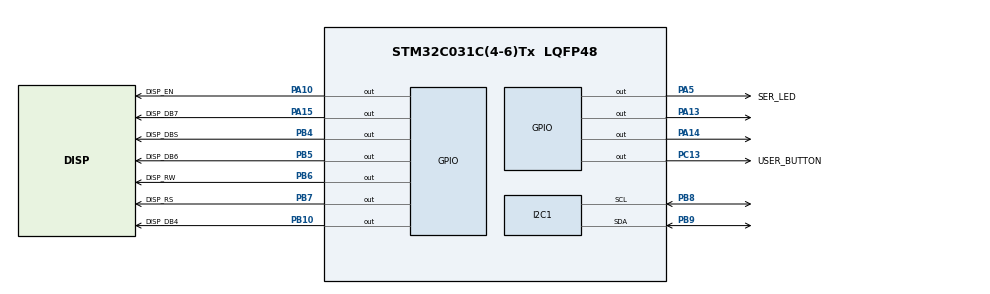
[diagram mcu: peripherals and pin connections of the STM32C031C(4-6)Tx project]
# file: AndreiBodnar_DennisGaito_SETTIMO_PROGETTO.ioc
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I2C1.Timing=0x10805D88
Mcu.Family=STM32C0
Mcu.Name=STM32C031C(4-6)Tx
Mcu.Package=LQFP48
PA10.GPIO_Label=DISP_EN
PA10.Signal=GPIO_Output
PA13.Signal=GPIO_Output
PA14-BOOT0.Signal=GPIO_Output
PA15.GPIO_Label=DISP_DB7
PA15.Signal=GPIO_Output
PA2.GPIO_Label=VCP_USART2_TX
PA2.Signal=USART2_TX
PA3.Signal=USART2_RX
PA5.GPIO_Label=SER_LED
PA5.Signal=GPIO_Output
PB10.GPIO_Label=DISP_DB4
PB10.Signal=GPIO_Output
PB4.GPIO_Label=DISP_DBS
PB4.Signal=GPIO_Output
PB5.GPIO_Label=DISP_DB6
PB5.Signal=GPIO_Output
PB6.GPIO_Label=DISP_RW
PB6.Signal=GPIO_Output
PB7.GPIO_Label=DISP_RS
PB7.Signal=GPIO_Output
PB8.Mode=I2C
PB8.Signal=I2C1_SCL
PB9.Mode=I2C
PB9.Signal=I2C1_SDA
PC13.GPIO_Label=USER_BUTTON
PC13.Signal=GPIO_Output
PC14-OSCX_IN\ (PC14).GPIO_Label=RCC_OSCX_IN
PC14-OSCX_IN\ (PC14).Mode=LSE-External-Oscillator
PC14-OSCX_IN\ (PC14).Signal=RCC_OSCX_IN
PC15-OSCX_OUT\ (PC15).GPIO_Label=RCC_OSCX_OUT
PC15-OSCX_OUT\ (PC15).Mode=LSE-External-Oscillator
PC15-OSCX_OUT\ (PC15).Signal=RCC_OSCX_OUT
PF0-OSC_IN\ (PF0).GPIO_Label=RCC_OSC_IN
PF0-OSC_IN\ (PF0).Mode=HSE-External-Oscillator
PF0-OSC_IN\ (PF0).Signal=RCC_OSC_IN
PF1-OSC_OUT\ (PF1).GPIO_Label=RCC_OSC_OUT
PF1-OSC_OUT\ (PF1).Mode=HSE-External-Oscillator
PF1-OSC_OUT\ (PF1).Signal=RCC_OSC_OUT
ProjectManager.HeapSize=0x200
ProjectManager.StackSize=0x400
ProjectManager.TargetToolchain=STM32CubeIDE
RCC.ADCFreq_Value=48000000
RCC.AHBFreq_Value=48000000
RCC.CortexFreq_Value=48000000
RCC.EXTERNAL_CLOCK_VALUE=12288000
RCC.HCLKFreq_Value=48000000
RCC.HSE_VALUE=48000000
RCC.HSISYSCLKDivider=RCC_HSI_DIV1
RCC.HSI_VALUE=48000000
RCC.SYSCLKFreq_VALUE=48000000
RCC.SYSCLKSource=RCC_SYSCLKSOURCE_HSE
board=NUCLEO-C031C6

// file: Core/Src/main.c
/* USER CODE BEGIN Header */
/**
  ******************************************************************************
  * @file           : main.c
  * @brief          : Main program body
  ******************************************************************************
  * @attention
  *
  * Copyright (c) 2026 STMicroelectronics.
  * All rights reserved.
  *
  * This software is licensed under terms that can be found in the LICENSE file
  * in the root directory of this software component.
  * If no LICENSE file comes with this software, it is provided AS-IS.
  *
  ******************************************************************************
  */
/* USER CODE END Header */
#include "main.h"

/* USER CODE BEGIN PD */
/* USER CODE BEGIN PD */
// Indirizzo shiftato a sinistra (0x18 << 1 = 0x30 oppure 0x19 << 1 = 0x32)
// Proviamo 0x30 (SDO a GND). Se non va, cambia in 0x32 dopo.
#define LIS2DW12_ADDR      0x3
#define LIS2DW12_WHO_REG   0x0F
#define LIS2DW12_WHO_VAL   0x44
/* USER CODE END PD */

I2C_HandleTypeDef hi2c1;

/* USER CODE BEGIN PV */
/* USER CODE BEGIN PV */
uint8_t sensor_id = 0;
HAL_StatusTypeDef ret_tx;
HAL_StatusTypeDef ret_rx;
uint8_t reg_to_read = LIS2DW12_WHO_REG;
/* USER CODE END PV */

void SystemClock_Config(void);
static void MX_GPIO_Init(void);
static void MX_I2C1_Init(void);

int main(void)
{

  /* USER CODE BEGIN 1 */
	HAL_StatusTypeDef ret; // Aggiungi questa variabile per il controllo
  /* USER CODE END 1 */

  /* MCU Configuration--------------------------------------------------------*/

  /* Reset of all peripherals, Initializes the Flash interface and the Systick. */
  HAL_Init();

  /* Configure the system clock */
  SystemClock_Config();

  /* Initialize all configured peripherals */
  MX_GPIO_Init();
  MX_I2C1_Init();
  /* USER CODE BEGIN 2 */
  /* USER CODE BEGIN 2 */

  // 1. Diciamo al sensore quale registro vogliamo leggere (Slide 29)
  ret_tx = HAL_I2C_Master_Transmit(&hi2c1, LIS2DW12_ADDR, &reg_to_read, 1, 100);

  // 2. Se la trasmissione è andata bene, leggiamo il risultato
  if (ret_tx == HAL_OK) {
      ret_rx = HAL_I2C_Master_Receive(&hi2c1, LIS2DW12_ADDR, &sensor_id, 1, 100);
  }

  /* USER CODE END 2 */

  /* Infinite loop */
  while (1)
  {

  }
}

void SystemClock_Config(void)
{
  RCC_OscInitTypeDef RCC_OscInitStruct = {0};
  RCC_ClkInitTypeDef RCC_ClkInitStruct = {0};

  __HAL_FLASH_SET_LATENCY(FLASH_LATENCY_1);

  /** Initializes the RCC Oscillators according to the specified parameters
  * in the RCC_OscInitTypeDef structure.
  */
  RCC_OscInitStruct.OscillatorType = RCC_OSCILLATORTYPE_HSE;
  RCC_OscInitStruct.HSEState = RCC_HSE_ON;
  if (HAL_RCC_OscConfig(&RCC_OscInitStruct) != HAL_OK)
  {
    Error_Handler();
  }

  /** Initializes the CPU, AHB and APB buses clocks
  */
  RCC_ClkInitStruct.ClockType = RCC_CLOCKTYPE_HCLK|RCC_CLOCKTYPE_SYSCLK
                              |RCC_CLOCKTYPE_PCLK1;
  RCC_ClkInitStruct.SYSCLKSource = RCC_SYSCLKSOURCE_HSE;
  RCC_ClkInitStruct.SYSCLKDivider = RCC_SYSCLK_DIV1;
  RCC_ClkInitStruct.AHBCLKDivider = RCC_HCLK_DIV1;
  RCC_ClkInitStruct.APB1CLKDivider = RCC_APB1_DIV1;

  if (HAL_RCC_ClockConfig(&RCC_ClkInitStruct, FLASH_LATENCY_1) != HAL_OK)
  {
    Error_Handler();
  }
}

static void MX_I2C1_Init(void)
{

  hi2c1.Instance = I2C1;
  hi2c1.Init.Timing = 0x10805D88;
  hi2c1.Init.OwnAddress1 = 0;
  hi2c1.Init.AddressingMode = I2C_ADDRESSINGMODE_7BIT;
  hi2c1.Init.DualAddressMode = I2C_DUALADDRESS_DISABLE;
  hi2c1.Init.OwnAddress2 = 0;
  hi2c1.Init.OwnAddress2Masks = I2C_OA2_NOMASK;
  hi2c1.Init.GeneralCallMode = I2C_GENERALCALL_DISABLE;
  hi2c1.Init.NoStretchMode = I2C_NOSTRETCH_DISABLE;
  if (HAL_I2C_Init(&hi2c1) != HAL_OK)
  {
    Error_Handler();
  }

  /** Configure Analogue filter
  */
  if (HAL_I2CEx_ConfigAnalogFilter(&hi2c1, I2C_ANALOGFILTER_ENABLE) != HAL_OK)
  {
    Error_Handler();
  }

  /** Configure Digital filter
  */
  if (HAL_I2CEx_ConfigDigitalFilter(&hi2c1, 0) != HAL_OK)
  {
    Error_Handler();
  }

}

static void MX_GPIO_Init(void)
{
  LL_GPIO_InitTypeDef GPIO_InitStruct = {0};

  /* GPIO Ports Clock Enable */
  LL_IOP_GRP1_EnableClock(LL_IOP_GRP1_PERIPH_GPIOC);
  LL_IOP_GRP1_EnableClock(LL_IOP_GRP1_PERIPH_GPIOF);
  LL_IOP_GRP1_EnableClock(LL_IOP_GRP1_PERIPH_GPIOA);
  LL_IOP_GRP1_EnableClock(LL_IOP_GRP1_PERIPH_GPIOB);

  /**/
  LL_GPIO_ResetOutputPin(USER_BUTTON_GPIO_Port, USER_BUTTON_Pin);

  /**/
  LL_GPIO_ResetOutputPin(SER_LED_GPIO_Port, SER_LED_Pin);

  /**/
  LL_GPIO_ResetOutputPin(DISP_DB4_GPIO_Port, DISP_DB4_Pin);

  /**/
  LL_GPIO_ResetOutputPin(DISP_EN_GPIO_Port, DISP_EN_Pin);

  /**/
  LL_GPIO_ResetOutputPin(GPIOA, LL_GPIO_PIN_13);

  /**/
  LL_GPIO_ResetOutputPin(GPIOA, LL_GPIO_PIN_14);

  /**/
  LL_GPIO_ResetOutputPin(DISP_DB7_GPIO_Port, DISP_DB7_Pin);

  /**/
  LL_GPIO_ResetOutputPin(DISP_DBS_GPIO_Port, DISP_DBS_Pin);

  /**/
  LL_GPIO_ResetOutputPin(DISP_DB6_GPIO_Port, DISP_DB6_Pin);

  /**/
  LL_GPIO_ResetOutputPin(DISP_RW_GPIO_Port, DISP_RW_Pin);

  /**/
  LL_GPIO_ResetOutputPin(DISP_RS_GPIO_Port, DISP_RS_Pin);

  /**/
  GPIO_InitStruct.Pin = USER_BUTTON_Pin;
  GPIO_InitStruct.Mode = LL_GPIO_MODE_OUTPUT;
  GPIO_InitStruct.Speed = LL_GPIO_SPEED_FREQ_LOW;
  GPIO_InitStruct.OutputType = LL_GPIO_OUTPUT_PUSHPULL;
  GPIO_InitStruct.Pull = LL_GPIO_PULL_NO;
  LL_GPIO_Init(USER_BUTTON_GPIO_Port, &GPIO_InitStruct);

  /**/
  GPIO_InitStruct.Pin = VCP_USART2_TX_Pin;
  GPIO_InitStruct.Mode = LL_GPIO_MODE_ALTERNATE;
  GPIO_InitStruct.Speed = LL_GPIO_SPEED_FREQ_LOW;
  GPIO_InitStruct.OutputType = LL_GPIO_OUTPUT_PUSHPULL;
  GPIO_InitStruct.Pull = LL_GPIO_PULL_NO;
  GPIO_InitStruct.Alternate = LL_GPIO_AF_1;
  LL_GPIO_Init(VCP_USART2_TX_GPIO_Port, &GPIO_InitStruct);

  /**/
  GPIO_InitStruct.Pin = LL_GPIO_PIN_3;
  GPIO_InitStruct.Mode = LL_GPIO_MODE_ALTERNATE;
  GPIO_InitStruct.Speed = LL_GPIO_SPEED_FREQ_LOW;
  GPIO_InitStruct.OutputType = LL_GPIO_OUTPUT_PUSHPULL;
  GPIO_InitStruct.Pull = LL_GPIO_PULL_NO;
  GPIO_InitStruct.Alternate = LL_GPIO_AF_1;
  LL_GPIO_Init(GPIOA, &GPIO_InitStruct);

  /**/
  GPIO_InitStruct.Pin = SER_LED_Pin;
  GPIO_InitStruct.Mode = LL_GPIO_MODE_OUTPUT;
  GPIO_InitStruct.Speed = LL_GPIO_SPEED_FREQ_LOW;
  GPIO_InitStruct.OutputType = LL_GPIO_OUTPUT_PUSHPULL;
  GPIO_InitStruct.Pull = LL_GPIO_PULL_NO;
  LL_GPIO_Init(SER_LED_GPIO_Port, &GPIO_InitStruct);

  /**/
  GPIO_InitStruct.Pin = DISP_DB4_Pin;
  GPIO_InitStruct.Mode = LL_GPIO_MODE_OUTPUT;
  GPIO_InitStruct.Speed = LL_GPIO_SPEED_FREQ_LOW;
  GPIO_InitStruct.OutputType = LL_GPIO_OUTPUT_PUSHPULL;
  GPIO_InitStruct.Pull = LL_GPIO_PULL_NO;
  LL_GPIO_Init(DISP_DB4_GPIO_Port, &GPIO_InitStruct);

  /**/
  GPIO_InitStruct.Pin = DISP_EN_Pin;
  GPIO_InitStruct.Mode = LL_GPIO_MODE_OUTPUT;
  GPIO_InitStruct.Speed = LL_GPIO_SPEED_FREQ_LOW;
  GPIO_InitStruct.OutputType = LL_GPIO_OUTPUT_PUSHPULL;
  GPIO_InitStruct.Pull = LL_GPIO_PULL_NO;
  LL_GPIO_Init(DISP_EN_GPIO_Port, &GPIO_InitStruct);

  /**/
  GPIO_InitStruct.Pin = LL_GPIO_PIN_13;
  GPIO_InitStruct.Mode = LL_GPIO_MODE_OUTPUT;
  GPIO_InitStruct.Speed = LL_GPIO_SPEED_FREQ_LOW;
  GPIO_InitStruct.OutputType = LL_GPIO_OUTPUT_PUSHPULL;
  GPIO_InitStruct.Pull = LL_GPIO_PULL_NO;
  LL_GPIO_Init(GPIOA, &GPIO_InitStruct);

  /**/
  GPIO_InitStruct.Pin = LL_GPIO_PIN_14;
  GPIO_InitStruct.Mode = LL_GPIO_MODE_OUTPUT;
  GPIO_InitStruct.Speed = LL_GPIO_SPEED_FREQ_LOW;
  GPIO_InitStruct.OutputType = LL_GPIO_OUTPUT_PUSHPULL;
  GPIO_InitStruct.Pull = LL_GPIO_PULL_NO;
  LL_GPIO_Init(GPIOA, &GPIO_InitStruct);

  /**/
  GPIO_InitStruct.Pin = DISP_DB7_Pin;
  GPIO_InitStruct.Mode = LL_GPIO_MODE_OUTPUT;
  GPIO_InitStruct.Speed = LL_GPIO_SPEED_FREQ_LOW;
  GPIO_InitStruct.OutputType = LL_GPIO_OUTPUT_PUSHPULL;
  GPIO_InitStruct.Pull = LL_GPIO_PULL_NO;
  LL_GPIO_Init(DISP_DB7_GPIO_Port, &GPIO_InitStruct);

  /**/
  GPIO_InitStruct.Pin = DISP_DBS_Pin;
  GPIO_InitStruct.Mode = LL_GPIO_MODE_OUTPUT;
  GPIO_InitStruct.Speed = LL_GPIO_SPEED_FREQ_LOW;
  GPIO_InitStruct.OutputType = LL_GPIO_OUTPUT_PUSHPULL;
  GPIO_InitStruct.Pull = LL_GPIO_PULL_NO;
  LL_GPIO_Init(DISP_DBS_GPIO_Port, &GPIO_InitStruct);

  /**/
  GPIO_InitStruct.Pin = DISP_DB6_Pin;
  GPIO_InitStruct.Mode = LL_GPIO_MODE_OUTPUT;
  GPIO_InitStruct.Speed = LL_GPIO_SPEED_FREQ_LOW;
  GPIO_InitStruct.OutputType = LL_GPIO_OUTPUT_PUSHPULL;
  GPIO_InitStruct.Pull = LL_GPIO_PULL_NO;
  LL_GPIO_Init(DISP_DB6_GPIO_Port, &GPIO_InitStruct);

  /**/
  GPIO_InitStruct.Pin = DISP_RW_Pin;
  GPIO_InitStruct.Mode = LL_GPIO_MODE_OUTPUT;
  GPIO_InitStruct.Speed = LL_GPIO_SPEED_FREQ_LOW;
  GPIO_InitStruct.OutputType = LL_GPIO_OUTPUT_PUSHPULL;
  GPIO_InitStruct.Pull = LL_GPIO_PULL_NO;
  LL_GPIO_Init(DISP_RW_GPIO_Port, &GPIO_InitStruct);

  /**/
  GPIO_InitStruct.Pin = DISP_RS_Pin;
  GPIO_InitStruct.Mode = LL_GPIO_MODE_OUTPUT;
  GPIO_InitStruct.Speed = LL_GPIO_SPEED_FREQ_LOW;
  GPIO_InitStruct.OutputType = LL_GPIO_OUTPUT_PUSHPULL;
  GPIO_InitStruct.Pull = LL_GPIO_PULL_NO;
  LL_GPIO_Init(DISP_RS_GPIO_Port, &GPIO_InitStruct);

}

void Error_Handler(void)
{
  __disable_irq();
  while (1)
  {
  }
}
